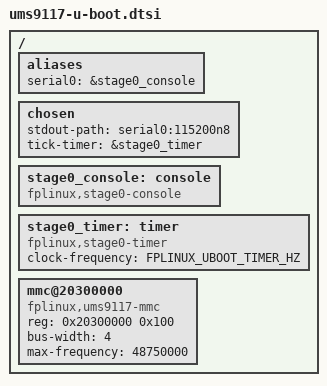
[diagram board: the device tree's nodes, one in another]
// SPDX-License-Identifier: GPL-2.0-only
/ {
	#address-cells = <1>;
	#size-cells = <1>;

	aliases {
		serial0 = &stage0_console;
	};

	chosen {
		stdout-path = "serial0:115200n8";
		tick-timer = &stage0_timer;
	};

#include "fplinux-uboot-layout.dtsi"

	stage0_console: console {
		compatible = "fplinux,stage0-console";
		bootph-all;
	};

	stage0_timer: timer {
		compatible = "fplinux,stage0-timer";
		clock-frequency = <FPLINUX_UBOOT_TIMER_HZ>;
		bootph-all;
	};

	mmc@20300000 {
		compatible = "fplinux,ums9117-mmc";
		reg = <0x20300000 0x100>;
		bus-width = <4>;
		max-frequency = <48750000>;
	};
};
